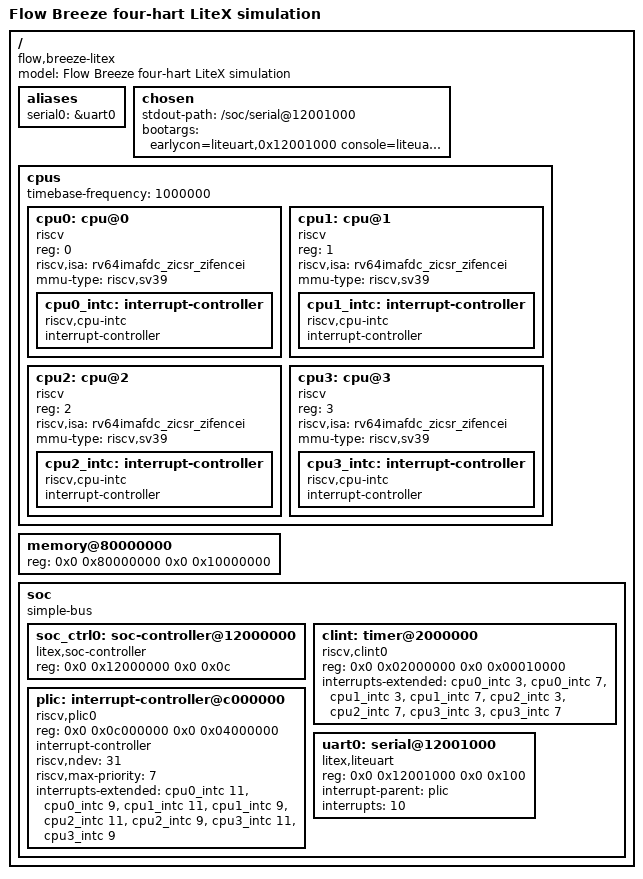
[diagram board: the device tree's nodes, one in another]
/dts-v1/;

/ {
	#address-cells = <2>;
	#size-cells = <2>;
	compatible = "flow,breeze-litex";
	model = "Flow Breeze four-hart LiteX simulation";
	aliases {
		serial0 = &uart0;
	};

	chosen {
		stdout-path = "/soc/serial@12001000";
		bootargs = "earlycon=liteuart,0x12001000 console=liteuart";
	};

	cpus {
		#address-cells = <1>;
		#size-cells = <0>;
		timebase-frequency = <1000000>;

		cpu0: cpu@0 {
			device_type = "cpu";
			reg = <0>;
			status = "okay";
			compatible = "riscv";
			riscv,isa = "rv64imafdc_zicsr_zifencei";
			mmu-type = "riscv,sv39";
			cpu0_intc: interrupt-controller {
				#address-cells = <0>;
				#interrupt-cells = <1>;
				interrupt-controller;
				compatible = "riscv,cpu-intc";
			};
		};

		cpu1: cpu@1 {
			device_type = "cpu";
			reg = <1>;
			status = "okay";
			compatible = "riscv";
			riscv,isa = "rv64imafdc_zicsr_zifencei";
			mmu-type = "riscv,sv39";
			cpu1_intc: interrupt-controller {
				#address-cells = <0>;
				#interrupt-cells = <1>;
				interrupt-controller;
				compatible = "riscv,cpu-intc";
			};
		};

		cpu2: cpu@2 {
			device_type = "cpu";
			reg = <2>;
			status = "okay";
			compatible = "riscv";
			riscv,isa = "rv64imafdc_zicsr_zifencei";
			mmu-type = "riscv,sv39";
			cpu2_intc: interrupt-controller {
				#address-cells = <0>;
				#interrupt-cells = <1>;
				interrupt-controller;
				compatible = "riscv,cpu-intc";
			};
		};

		cpu3: cpu@3 {
			device_type = "cpu";
			reg = <3>;
			status = "okay";
			compatible = "riscv";
			riscv,isa = "rv64imafdc_zicsr_zifencei";
			mmu-type = "riscv,sv39";
			cpu3_intc: interrupt-controller {
				#address-cells = <0>;
				#interrupt-cells = <1>;
				interrupt-controller;
				compatible = "riscv,cpu-intc";
			};
		};
	};

	memory@80000000 {
		device_type = "memory";
		reg = <0x0 0x80000000 0x0 0x10000000>;
	};

	soc {
		#address-cells = <2>;
		#size-cells = <2>;
		compatible = "simple-bus";
		ranges;

		soc_ctrl0: soc-controller@12000000 {
			compatible = "litex,soc-controller";
			reg = <0x0 0x12000000 0x0 0x0c>;
			status = "okay";
		};

		clint: timer@2000000 {
			compatible = "riscv,clint0";
			reg = <0x0 0x02000000 0x0 0x00010000>;
			interrupts-extended = <
				&cpu0_intc 3 &cpu0_intc 7
				&cpu1_intc 3 &cpu1_intc 7
				&cpu2_intc 3 &cpu2_intc 7
				&cpu3_intc 3 &cpu3_intc 7
			>;
		};

		plic: interrupt-controller@c000000 {
			#address-cells = <0>;
			compatible = "riscv,plic0";
			reg = <0x0 0x0c000000 0x0 0x04000000>;
			#interrupt-cells = <1>;
			interrupt-controller;
			riscv,ndev = <31>;
			riscv,max-priority = <7>;
			interrupts-extended = <
				&cpu0_intc 11 &cpu0_intc 9
				&cpu1_intc 11 &cpu1_intc 9
				&cpu2_intc 11 &cpu2_intc 9
				&cpu3_intc 11 &cpu3_intc 9
			>;
		};

		uart0: serial@12001000 {
			compatible = "litex,liteuart";
			reg = <0x0 0x12001000 0x0 0x100>;
			interrupt-parent = <&plic>;
			interrupts = <10>;
			status = "okay";
		};
	};
};
